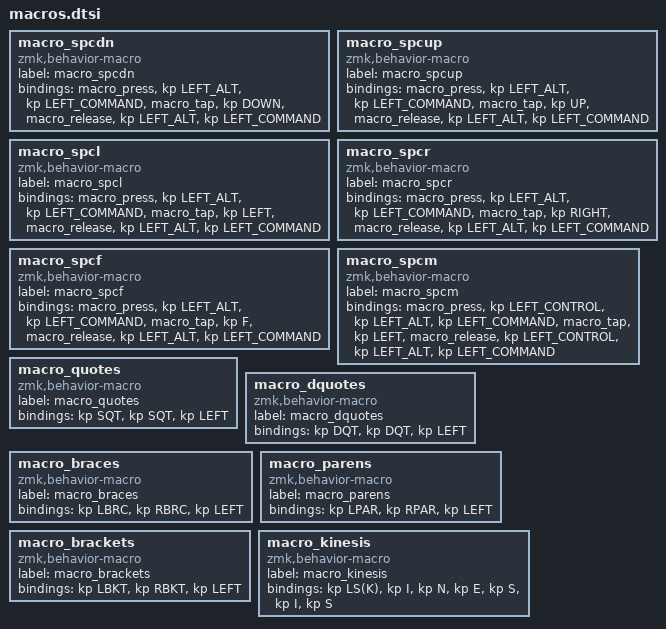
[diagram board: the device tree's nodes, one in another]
macro_spcdn: macro_spcdn{
compatible = "zmk,behavior-macro";
label = "macro_spcdn";
#binding-cells = <0>;
bindings = <&macro_press &kp LEFT_ALT &kp LEFT_COMMAND>, <&macro_tap &kp DOWN>, <&macro_release &kp LEFT_ALT &kp LEFT_COMMAND>;
};
macro_spcup: macro_spcup{
compatible = "zmk,behavior-macro";
label = "macro_spcup";
#binding-cells = <0>;
bindings = <&macro_press &kp LEFT_ALT &kp LEFT_COMMAND>, <&macro_tap &kp UP>, <&macro_release &kp LEFT_ALT &kp LEFT_COMMAND>;
};
macro_spcl: macro_spcl{
compatible = "zmk,behavior-macro";
label = "macro_spcl";
#binding-cells = <0>;
bindings = <&macro_press &kp LEFT_ALT &kp LEFT_COMMAND>, <&macro_tap &kp LEFT>, <&macro_release &kp LEFT_ALT &kp LEFT_COMMAND>;
};
macro_spcr: macro_spcr{
compatible = "zmk,behavior-macro";
label = "macro_spcr";
#binding-cells = <0>;
bindings = <&macro_press &kp LEFT_ALT &kp LEFT_COMMAND>, <&macro_tap &kp RIGHT>, <&macro_release &kp LEFT_ALT &kp LEFT_COMMAND>;
};
macro_spcf: macro_spcf{
compatible = "zmk,behavior-macro";
label = "macro_spcf";
#binding-cells = <0>;
bindings = <&macro_press &kp LEFT_ALT &kp LEFT_COMMAND>, <&macro_tap &kp F>, <&macro_release &kp LEFT_ALT &kp LEFT_COMMAND>;
};
macro_spcm: macro_spcm{
compatible = "zmk,behavior-macro";
label = "macro_spcm";
#binding-cells = <0>;
bindings = <&macro_press &kp LEFT_CONTROL &kp LEFT_ALT &kp LEFT_COMMAND>, <&macro_tap &kp LEFT>, <&macro_release &kp LEFT_CONTROL &kp LEFT_ALT &kp LEFT_COMMAND>;
};
macro_quotes: macro_quotes{
compatible = "zmk,behavior-macro";
label = "macro_quotes";
#binding-cells = <0>;
bindings = <&kp SQT>, <&kp SQT>, <&kp LEFT>;
};
macro_dquotes: macro_dquotes{
compatible = "zmk,behavior-macro";
label = "macro_dquotes";
#binding-cells = <0>;
bindings = <&kp DQT>, <&kp DQT>, <&kp LEFT>;
};
macro_braces: macro_braces{
compatible = "zmk,behavior-macro";
label = "macro_braces";
#binding-cells = <0>;
bindings = <&kp LBRC>, <&kp RBRC>, <&kp LEFT>;
};
macro_parens: macro_parens{
compatible = "zmk,behavior-macro";
label = "macro_parens";
#binding-cells = <0>;
bindings = <&kp LPAR>, <&kp RPAR>, <&kp LEFT>;
};
macro_brackets: macro_brackets{
compatible = "zmk,behavior-macro";
label = "macro_brackets";
#binding-cells = <0>;
bindings = <&kp LBKT>, <&kp RBKT>, <&kp LEFT>;
};
macro_kinesis: macro_kinesis{
compatible = "zmk,behavior-macro";
label = "macro_kinesis";
#binding-cells = <0>;
bindings = <&kp LS(K)>, <&kp I>, <&kp N>, <&kp E>, <&kp S>, <&kp I>, <&kp S>;
};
